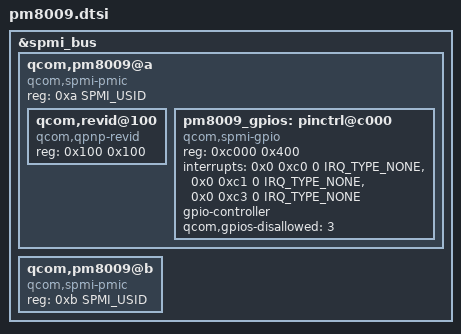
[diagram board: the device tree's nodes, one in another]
/* Copyright (c) 2018, The Linux Foundation. All rights reserved.
 *
 * This program is free software; you can redistribute it and/or modify
 * it under the terms of the GNU General Public License version 2 and
 * only version 2 as published by the Free Software Foundation.
 *
 * This program is distributed in the hope that it will be useful,
 * but WITHOUT ANY WARRANTY; without even the implied warranty of
 * MERCHANTABILITY or FITNESS FOR A PARTICULAR PURPOSE.  See the
 * GNU General Public License for more details.
 */

#include <dt-bindings/spmi/spmi.h>

&spmi_bus {
	qcom,pm8009@a {
		compatible ="qcom,spmi-pmic";
		reg = <0xa SPMI_USID>;
		#address-cells = <1>;
		#size-cells = <1>;

		qcom,revid@100 {
			compatible = "qcom,qpnp-revid";
			reg = <0x100 0x100>;
		};

		pm8009_gpios: pinctrl@c000 {
			compatible = "qcom,spmi-gpio";
			reg = <0xc000 0x400>;
			interrupts = <0x0 0xc0 0 IRQ_TYPE_NONE>,
				     <0x0 0xc1 0 IRQ_TYPE_NONE>,
				     <0x0 0xc3 0 IRQ_TYPE_NONE>;
			interrupt-names = "pm8009_gpio1",  "pm8009_gpio2",
					  "pm8009_gpio4";
			gpio-controller;
			#gpio-cells = <2>;
			qcom,gpios-disallowed = <3>;
		};
	};

	qcom,pm8009@b {
		compatible = "qcom,spmi-pmic";
		reg = <0xb SPMI_USID>;
		#address-cells = <1>;
		#size-cells = <1>;
	};
};
